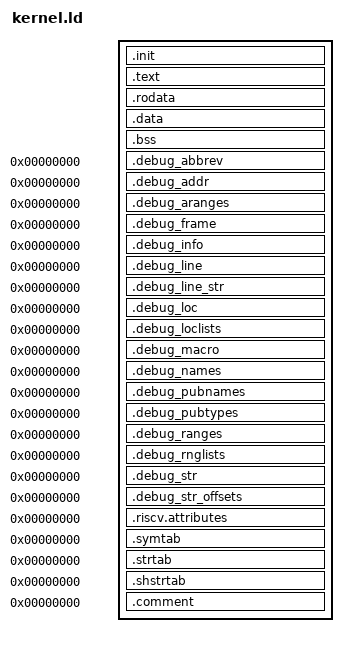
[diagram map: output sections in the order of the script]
/* ============================================================================
 *  RISC-V 32-bit kernel linker script
 *
 *  TARGET:  riscv32imac-unknown-none-elf (built without compressed instructions)
 *  FORMAT:  ELF32 RISC-V, little-endian
 *  LOAD:    LiteX BIOS loads the raw binary at 0x40000000
 *
 *  RISC-V BACKGROUND
 *  For the RV32IMA + Sv32 loader contract:
 *    - LiteX BIOS jumps to the kernel in MACHINE mode at 0x40000000
 *    - The first instruction at 0x40000000 MUST be the entry point (_start)
 *    - boot.s initializes the boot environment and enters SUPERVISOR mode
 *    - Paging later maps the kernel at virtual address 0xff000000
 *  ============================================================================
 */

OUTPUT_ARCH(riscv)

/*
 * This kernel is linked at a high virtual address but starts executing from
 * its physical load address before paging is enabled. The early image relies
 * on medany-style PC-relative code generation:
 *
 *   Rust/LLVM: -C code-model=medium -C relocation-model=static
 *   Linker:    --no-relax
 *
 * Do not use absolute addresses or GP-relative relaxation in early boot code
 * unless gp and the matching virtual mapping are already established.
 *
 * board.ld supplies the physical load address. build.rs supplies the virtual
 * layout and page and stack sizes from runtime/src/arch/rv/rv32/consts.rs.
 */

/* ---------------------------------------------------------------------------
 *  ENTRY
 *  Declares the runtime entry point symbol (does NOT set the binary offset).
 *  The linker records this in the ELF header's e_entry field.
 *  LiteX BIOS enters the raw binary without consulting ELF headers, so the
 *  real guarantee comes from PLACING _start FIRST via .text.init below.
 * ------------------------------------------------------------------------- */
ENTRY(_start)

KERNEL_VMA_OFFSET = KERNEL_VMA_BASE - KERNEL_LMA_BASE;

/* ---------------------------------------------------------------------------
 *  PHDRS (Program Headers)
 *  Defines ELF loadable segments. Each output section below maps to one of
 *  these via ":text" / ":rodata" / ":data" / ":bss".
 *
 *  PT_LOAD = a segment that gets loaded into memory by an ELF-aware loader.
 *  LiteX BIOS loads the flat binary; these headers describe the ELF layout
 *  for debuggers and inspection tools. Runtime page tables set permissions:
 *    text   -> readable + executable
 *    rodata -> readable only
 *    data   -> readable + writable
 *    bss    -> readable + writable
 * ------------------------------------------------------------------------- */
PHDRS
{
  text PT_LOAD;
  rodata PT_LOAD;
  data PT_LOAD;
  bss PT_LOAD;
}

SECTIONS
{
  /* The location counter tracks virtual addresses (VMA). AT(...) supplies
     physical load addresses (LMA); their difference is KERNEL_VMA_OFFSET. */
  . = KERNEL_VMA_BASE;
  _kernel_start = .;
  ASSERT(KERNEL_LMA_BASE % HUGE_PAGE_SIZE == 0, "unaligned Sv32 kernel load address")
  ASSERT(KERNEL_LMA_BASE + KERNEL_VMA_SIZE <= DIRECT_VMA_SIZE,
         "kernel image window exceeds physical direct map")

  /* ========================================================================
   *  .init — Reclaimable boot-time code and data
   *
   *  PURPOSE:
   *  - Keep _start at binary offset 0 (= KERNEL_LMA_BASE).
   *  - Gather explicitly annotated boot-time input sections and the boot
   *    stack into one page-aligned range for later reclamation.
   *
   *  Function section annotations do not automatically move compiler-generated
   *  anonymous rodata, such as string literals and panic metadata. Those may
   *  remain in .rodata even when the referencing function is in .init.text.
   * ======================================================================== */
  .init : AT(KERNEL_LMA_BASE)
  {
    _init_start = .;
    KEEP(*(.text.init))            /* _start must remain the first byte. */
    *(.init.text .init.text.*)
    *(.init.rodata .init.rodata.*)
    *(.init.data .init.data.*)

    /* boot.s clears this range in 32-bit words, including the boot stack.
       Unlike .bss below, this range is part of the loadable .init section. */
    . = ALIGN(4);
    _init_bss_start = .;
    *(.init.bss .init.bss.*)

    /* The boot hart uses this stack until it switches to a runtime stack.
       RISC-V requires the stack pointer to remain 16-byte aligned. */
    . = ALIGN(16);
    boot_stack = .;
    . += STACK_SIZE;
    boot_stack_top = .;

    . = ALIGN(PAGE_SIZE);
    _init_bss_end = .;
    _init_end = .;
  } :text

  /* ========================================================================
   *  .text — Main kernel code
   *
   *  *(.text .text.*) collects both the default code section and function-
   *  specific subsections generated by the compiler.
   *
   *  _text_start / _text_end delimit the executable runtime mapping. Rounding
   *  the end up to PAGE_SIZE keeps executable text and read-only/NX rodata on
   *  separate pages. Subsequent sections use LMA = VMA - KERNEL_VMA_OFFSET.
   * ======================================================================== */
  .text : AT(ADDR(.text) - KERNEL_VMA_OFFSET)
  {
    _text_start = .;
    *(.text .text.*)
    . = ALIGN(PAGE_SIZE);
    _text_end = .;
  } :text

  /* ========================================================================
   *  .rodata — Read-only data
   *
   *  Stores string literals, constants, jump tables, vtables, and small
   *  read-only data (.srodata). The separate segment and page-aligned bounds
   *  describe the range mapped read-only/NX by the runtime page table.
   *
   *  _rodata_start / _rodata_end: boundaries for permission setting.
   * ======================================================================== */
  .rodata : AT(ADDR(.rodata) - KERNEL_VMA_OFFSET)
  {
    _rodata_start = .;
    _kernel_vma_offset = .;
    LONG(KERNEL_VMA_OFFSET)
    *(.rodata .rodata.* .srodata .srodata.*)
    . = ALIGN(PAGE_SIZE);
    _rodata_end = .;
  } :rodata

  /* ========================================================================
   *  .data — Writable data (initialized globals / statics)
   *
   *  Collects regular .data and RISC-V small-data sections (.sdata), which
   *  can be used for GP-relative addressing when gp is initialized.
   *
   *  _data_start / _data_end delimit the writable initialized-data range.
   *  Page-aligned boundaries keep read-only rodata and writable data separate.
   * ======================================================================== */
  .data : AT(ADDR(.data) - KERNEL_VMA_OFFSET)
  {
    _data_start = .;
    *(.data .data.* .sdata .sdata.*)
    . = ALIGN(PAGE_SIZE);
    _data_end = .;
  } :data

  /* ========================================================================
   *  .bss — Zero-initialized data
   *
   *  Stores globals/statics that start at zero, including RISC-V small-BSS
   *  sections (.sbss). NOLOAD reserves memory without storing the section's
   *  contents in the image. boot.s clears _bss_start .. _bss_end at runtime,
   *  separately from the boot-time BSS range inside .init.
   *
   *  The end is rounded up to PAGE_SIZE so _kernel_end also marks a complete
   *  page boundary for runtime memory accounting.
   * ======================================================================== */
  .bss (NOLOAD) : AT(ADDR(.bss) - KERNEL_VMA_OFFSET)
  {
    _bss_start = .;
    *(.bss .bss.* .sbss .sbss.*)
    . = ALIGN(PAGE_SIZE);
    _bss_end = .;
  } :bss
  _kernel_end = .;

  /* Validate the raw-image entry and total in-memory footprint, including
     BSS and the boot stack, against the OS kernel virtual-address window.
     The image builder checks physical RAM capacity and firmware reservations. */
  ASSERT(_start == KERNEL_VMA_BASE, "entry must be the first image byte")
  ASSERT(_kernel_end - KERNEL_VMA_BASE < KERNEL_VMA_SIZE, "kernel exceeds virtual image window")

  /* ========================================================================
   *  Non-runtime metadata
   *
   *  These sections are intentionally placed at VMA 0 and are not assigned to
   *  a PT_LOAD segment. They remain in the ELF for debuggers, tooling, and
   *  target metadata, but they are not part of the loaded kernel image and are
   *  ignored when objcopy creates the flat binary.
   *
   *  Listing them here also keeps --orphan-handling=error useful: any new
   *  allocatable runtime section must be handled explicitly instead of being
   *  silently placed by the linker.
   * ======================================================================== */

  /* DWARF debug sections kept for kernel.elf/kernel.debug symbolication. */
  .debug_abbrev 0 : { *(.debug_abbrev) *(.debug_abbrev.*) }
  .debug_addr 0 : { *(.debug_addr) *(.debug_addr.*) }
  .debug_aranges 0 : { *(.debug_aranges) *(.debug_aranges.*) }
  .debug_frame 0 : { *(.debug_frame) *(.debug_frame.*) }
  .debug_info 0 : { *(.debug_info .debug_info.*) }
  .debug_line 0 : { *(.debug_line) *(.debug_line.*) }
  .debug_line_str 0 : { *(.debug_line_str) *(.debug_line_str.*) }
  .debug_loc 0 : { *(.debug_loc) *(.debug_loc.*) }
  .debug_loclists 0 : { *(.debug_loclists) *(.debug_loclists.*) }
  .debug_macro 0 : { *(.debug_macro) *(.debug_macro.*) }
  .debug_names 0 : { *(.debug_names) *(.debug_names.*) }
  .debug_pubnames 0 : { *(.debug_pubnames) *(.debug_pubnames.*) }
  .debug_pubtypes 0 : { *(.debug_pubtypes) *(.debug_pubtypes.*) }
  .debug_ranges 0 : { *(.debug_ranges) *(.debug_ranges.*) }
  .debug_rnglists 0 : { *(.debug_rnglists) *(.debug_rnglists.*) }
  .debug_str 0 : { *(.debug_str) *(.debug_str.*) }
  .debug_str_offsets 0 : { *(.debug_str_offsets) *(.debug_str_offsets.*) }

  /* RISC-V ABI/ISA attributes consumed by ELF-aware tools. */
  .riscv.attributes 0 : { *(.riscv.attributes) }

  /* ELF symbol and string tables used by debuggers and inspection tools. */
  .symtab 0 : { *(.symtab) }
  .strtab 0 : { *(.strtab) }
  .shstrtab 0 : { *(.shstrtab) }

  /* Compiler/linker provenance; useful for inspection, never loaded. */
  .comment 0 : { *(.comment) }

  /* This kernel has no stack unwinder yet, so discard unwind metadata. */
  /DISCARD/ : {
    *(.eh_frame)
    *(.eh_frame.*)
    *(.eh_frame_hdr)
  }
}
